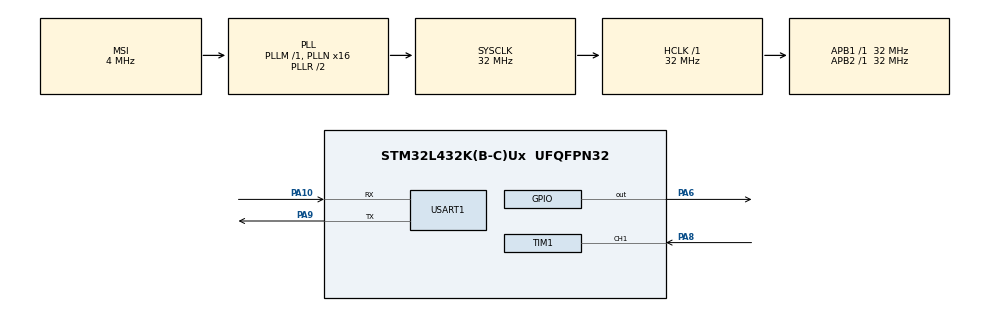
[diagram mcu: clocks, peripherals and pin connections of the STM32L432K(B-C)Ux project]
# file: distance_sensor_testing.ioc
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Mcu.Family=STM32L4
Mcu.Name=STM32L432K(B-C)Ux
Mcu.Package=UFQFPN32
NVIC.PriorityGroup=NVIC_PRIORITYGROUP_4
NVIC.TIM1_CC_IRQn=true\:0\:0\:false\:false\:true\:true\:true
NVIC.USART1_IRQn=true\:0\:0\:false\:false\:true\:true\:true
PA10.Mode=Asynchronous
PA10.Signal=USART1_RX
PA13\ (JTMS-SWDIO).Mode=Serial_Wire
PA13\ (JTMS-SWDIO).Signal=SYS_JTMS-SWDIO
PA14\ (JTCK-SWCLK).Mode=Serial_Wire
PA14\ (JTCK-SWCLK).Signal=SYS_JTCK-SWCLK
PA6.Signal=GPIO_Output
PA8.Signal=S_TIM1_CH1
PA9.Mode=Asynchronous
PA9.Signal=USART1_TX
PC14-OSC32_IN\ (PC14).Mode=LSE-External-Oscillator
PC14-OSC32_IN\ (PC14).Signal=RCC_OSC32_IN
PC15-OSC32_OUT\ (PC15).Mode=LSE-External-Oscillator
PC15-OSC32_OUT\ (PC15).Signal=RCC_OSC32_OUT
ProjectManager.HeapSize=0x200
ProjectManager.StackSize=0x400
ProjectManager.TargetToolchain=MDK-ARM V5
RCC.AHBFreq_Value=32000000
RCC.APB1Freq_Value=32000000
RCC.APB1TimFreq_Value=32000000
RCC.APB2Freq_Value=32000000
RCC.APB2TimFreq_Value=32000000
RCC.CortexFreq_Value=32000000
RCC.HCLKFreq_Value=32000000
RCC.HSE_VALUE=8000000
RCC.HSI48_VALUE=48000000
RCC.HSI_VALUE=16000000
RCC.MSI_VALUE=4000000
RCC.PLLN=16
RCC.SYSCLKFreq_VALUE=32000000
RCC.SYSCLKSource=RCC_SYSCLKSOURCE_PLLCLK
RCC.VCOOutputFreq_Value=64000000
SH.S_TIM1_CH1.0=TIM1_CH1,Input_Capture1_from_TI1
TIM1.Channel-Input_Capture1_from_TI1=TIM_CHANNEL_1
TIM1.Period=0xffff-1
TIM1.Prescaler=72-1
USART1.VirtualMode-Asynchronous=VM_ASYNC
board=custom

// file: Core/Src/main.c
/* USER CODE BEGIN Header */
/**
  ******************************************************************************
  * @file           : main.c
  * @brief          : Main program body
  ******************************************************************************
  * @attention
  *
  * <h2><center>&copy; Copyright (c) 2021 STMicroelectronics.
  * All rights reserved.</center></h2>
  *
  * This software component is licensed by ST under BSD 3-Clause license,
  * the "License"; You may not use this file except in compliance with the
  * License. You may obtain a copy of the License at:
  *                        opensource.org/licenses/BSD-3-Clause
  *
  ******************************************************************************
  */
/* USER CODE END Header */
#include "main.h"

TIM_HandleTypeDef htim1;

UART_HandleTypeDef huart1;

uint32_t local_time, sensor_time;
uint32_t distance;

void SystemClock_Config(void);
static void MX_GPIO_Init(void);
static void MX_TIM1_Init(void);
static void MX_USART1_UART_Init(void);
uint32_t hcsr04_read (void);

int main(void)
{
  /* USER CODE BEGIN 1 */
		uint8_t out[] = {0,0,0,'\r','\n'};
  /* USER CODE END 1 */

  /* MCU Configuration--------------------------------------------------------*/

  /* Reset of all peripherals, Initializes the Flash interface and the Systick. */
  HAL_Init();

  /* Configure the system clock */
  SystemClock_Config();

  /* Initialize all configured peripherals */
  MX_GPIO_Init();
  MX_TIM1_Init();
  MX_USART1_UART_Init();

  /* Infinite loop */
  while (1)
  {
		sensor_time = hcsr04_read();
		distance  = sensor_time * .034/2;

		HAL_Delay(200);

		out[2] = distance%10;
		distance = distance/10;

		out[1] = distance%10;
		distance = distance/10;

		out[0] = distance%10;
		distance = distance/10;

		HAL_UART_Transmit(&huart1,out, sizeof(out), 10);

  }
}

void SystemClock_Config(void)
{
  RCC_OscInitTypeDef RCC_OscInitStruct = {0};
  RCC_ClkInitTypeDef RCC_ClkInitStruct = {0};
  RCC_PeriphCLKInitTypeDef PeriphClkInit = {0};

  /** Configure LSE Drive Capability
  */
  HAL_PWR_EnableBkUpAccess();
  __HAL_RCC_LSEDRIVE_CONFIG(RCC_LSEDRIVE_LOW);
  /** Initializes the RCC Oscillators according to the specified parameters
  * in the RCC_OscInitTypeDef structure.
  */
  RCC_OscInitStruct.OscillatorType = RCC_OSCILLATORTYPE_LSE|RCC_OSCILLATORTYPE_MSI;
  RCC_OscInitStruct.LSEState = RCC_LSE_ON;
  RCC_OscInitStruct.MSIState = RCC_MSI_ON;
  RCC_OscInitStruct.MSICalibrationValue = 0;
  RCC_OscInitStruct.MSIClockRange = RCC_MSIRANGE_6;
  RCC_OscInitStruct.PLL.PLLState = RCC_PLL_ON;
  RCC_OscInitStruct.PLL.PLLSource = RCC_PLLSOURCE_MSI;
  RCC_OscInitStruct.PLL.PLLM = 1;
  RCC_OscInitStruct.PLL.PLLN = 16;
  RCC_OscInitStruct.PLL.PLLP = RCC_PLLP_DIV7;
  RCC_OscInitStruct.PLL.PLLQ = RCC_PLLQ_DIV2;
  RCC_OscInitStruct.PLL.PLLR = RCC_PLLR_DIV2;
  if (HAL_RCC_OscConfig(&RCC_OscInitStruct) != HAL_OK)
  {
    Error_Handler();
  }
  /** Initializes the CPU, AHB and APB buses clocks
  */
  RCC_ClkInitStruct.ClockType = RCC_CLOCKTYPE_HCLK|RCC_CLOCKTYPE_SYSCLK
                              |RCC_CLOCKTYPE_PCLK1|RCC_CLOCKTYPE_PCLK2;
  RCC_ClkInitStruct.SYSCLKSource = RCC_SYSCLKSOURCE_PLLCLK;
  RCC_ClkInitStruct.AHBCLKDivider = RCC_SYSCLK_DIV1;
  RCC_ClkInitStruct.APB1CLKDivider = RCC_HCLK_DIV1;
  RCC_ClkInitStruct.APB2CLKDivider = RCC_HCLK_DIV1;

  if (HAL_RCC_ClockConfig(&RCC_ClkInitStruct, FLASH_LATENCY_1) != HAL_OK)
  {
    Error_Handler();
  }
  PeriphClkInit.PeriphClockSelection = RCC_PERIPHCLK_USART1;
  PeriphClkInit.Usart1ClockSelection = RCC_USART1CLKSOURCE_PCLK2;
  if (HAL_RCCEx_PeriphCLKConfig(&PeriphClkInit) != HAL_OK)
  {
    Error_Handler();
  }
  /** Configure the main internal regulator output voltage
  */
  if (HAL_PWREx_ControlVoltageScaling(PWR_REGULATOR_VOLTAGE_SCALE1) != HAL_OK)
  {
    Error_Handler();
  }
  /** Enable MSI Auto calibration
  */
  HAL_RCCEx_EnableMSIPLLMode();
}

static void MX_TIM1_Init(void)
{

  TIM_MasterConfigTypeDef sMasterConfig = {0};
  TIM_IC_InitTypeDef sConfigIC = {0};

  htim1.Instance = TIM1;
  htim1.Init.Prescaler = 72-1;
  htim1.Init.CounterMode = TIM_COUNTERMODE_UP;
  htim1.Init.Period = 0xffff-1;
  htim1.Init.ClockDivision = TIM_CLOCKDIVISION_DIV1;
  htim1.Init.RepetitionCounter = 0;
  htim1.Init.AutoReloadPreload = TIM_AUTORELOAD_PRELOAD_DISABLE;
  if (HAL_TIM_IC_Init(&htim1) != HAL_OK)
  {
    Error_Handler();
  }
  sMasterConfig.MasterOutputTrigger = TIM_TRGO_RESET;
  sMasterConfig.MasterOutputTrigger2 = TIM_TRGO2_RESET;
  sMasterConfig.MasterSlaveMode = TIM_MASTERSLAVEMODE_DISABLE;
  if (HAL_TIMEx_MasterConfigSynchronization(&htim1, &sMasterConfig) != HAL_OK)
  {
    Error_Handler();
  }
  sConfigIC.ICPolarity = TIM_INPUTCHANNELPOLARITY_RISING;
  sConfigIC.ICSelection = TIM_ICSELECTION_DIRECTTI;
  sConfigIC.ICPrescaler = TIM_ICPSC_DIV1;
  sConfigIC.ICFilter = 0;
  if (HAL_TIM_IC_ConfigChannel(&htim1, &sConfigIC, TIM_CHANNEL_1) != HAL_OK)
  {
    Error_Handler();
  }

}

static void MX_USART1_UART_Init(void)
{

  huart1.Instance = USART1;
  huart1.Init.BaudRate = 115200;
  huart1.Init.WordLength = UART_WORDLENGTH_8B;
  huart1.Init.StopBits = UART_STOPBITS_1;
  huart1.Init.Parity = UART_PARITY_NONE;
  huart1.Init.Mode = UART_MODE_TX_RX;
  huart1.Init.HwFlowCtl = UART_HWCONTROL_NONE;
  huart1.Init.OverSampling = UART_OVERSAMPLING_16;
  huart1.Init.OneBitSampling = UART_ONE_BIT_SAMPLE_DISABLE;
  huart1.AdvancedInit.AdvFeatureInit = UART_ADVFEATURE_NO_INIT;
  if (HAL_UART_Init(&huart1) != HAL_OK)
  {
    Error_Handler();
  }

}

static void MX_GPIO_Init(void)
{
  GPIO_InitTypeDef GPIO_InitStruct = {0};

  /* GPIO Ports Clock Enable */
  __HAL_RCC_GPIOC_CLK_ENABLE();
  __HAL_RCC_GPIOA_CLK_ENABLE();

  /*Configure GPIO pin Output Level */
  HAL_GPIO_WritePin(GPIOA, GPIO_PIN_6, GPIO_PIN_RESET);

  /*Configure GPIO pin : PA6 */
  GPIO_InitStruct.Pin = GPIO_PIN_6;
  GPIO_InitStruct.Mode = GPIO_MODE_OUTPUT_PP;
  GPIO_InitStruct.Pull = GPIO_NOPULL;
  GPIO_InitStruct.Speed = GPIO_SPEED_FREQ_LOW;
  HAL_GPIO_Init(GPIOA, &GPIO_InitStruct);

}

/* USER CODE BEGIN 4 */

uint32_t hcsr04_read (void)
{
	__disable_irq();
 local_time=0;
 HAL_GPIO_WritePin(GPIOA, GPIO_PIN_6, GPIO_PIN_RESET);  // pull the TRIG pin HIGH
 HAL_Delay(2);

 HAL_GPIO_WritePin(GPIOA, GPIO_PIN_6, GPIO_PIN_SET);  // pull the TRIG pin HIGH
 HAL_Delay(10); // wait for 10 us
 HAL_GPIO_WritePin(GPIOA, GPIO_PIN_6, GPIO_PIN_RESET);  // pull the TRIG pin low

 // read the time for which the pin is high

 while (!(HAL_GPIO_ReadPin(GPIOA, GPIO_PIN_8)));  // wait for the ECHO pin to go high
 while (HAL_GPIO_ReadPin(GPIOA, GPIO_PIN_8))    // while the pin is high
  {
  local_time++;   // measure time for which the pin is high
  HAL_Delay(1);
  }

	__enable_irq();
 return local_time;
}
/* USER CODE END 4 */

void Error_Handler(void)
{
  __disable_irq();
  while (1)
  {
  }
}

/************************ (C) COPYRIGHT STMicroelectronics *****END OF FILE****/
